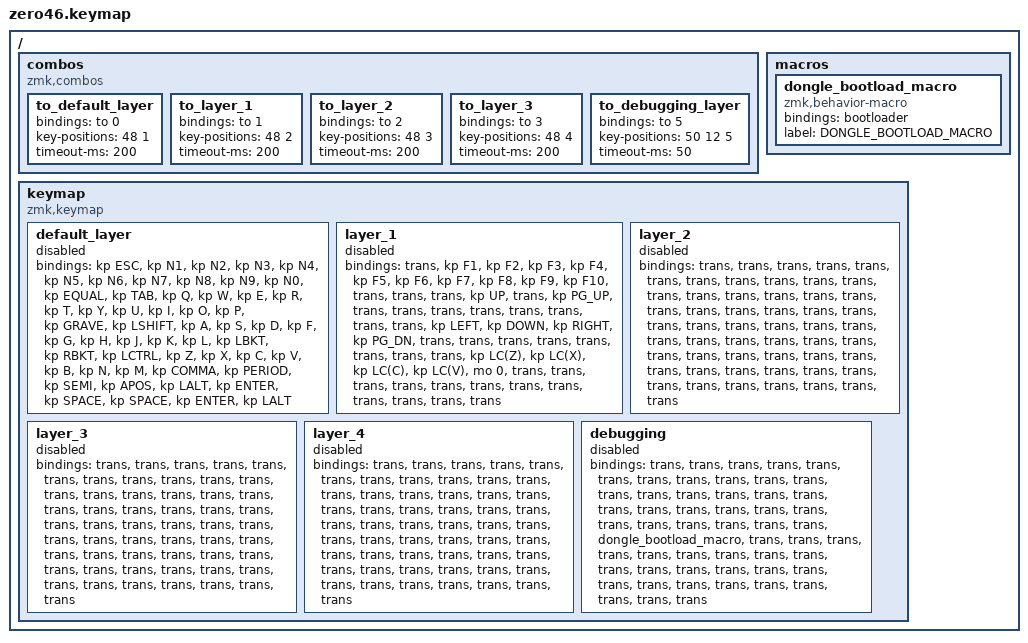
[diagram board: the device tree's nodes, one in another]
/*
 * Copyright (c) 2021 The ZMK Contributors
 *
 * SPDX-License-Identifier: MIT
 */
#define ZMK_BEHAVIORS_OMIT_KT
#include <behaviors.dtsi>
#include <dt-bindings/zmk/keys.h>

/ {
    combos {
        compatible = "zmk,combos";

        to_default_layer {
            bindings = <&to 0>;
            key-positions = <48 1>;
            timeout-ms = <200>;
        };

        to_layer_1 {
            bindings = <&to 1>;
            key-positions = <48 2>;
            timeout-ms = <200>;
        };

        to_layer_2 {
            bindings = <&to 2>;
            key-positions = <48 3>;
            timeout-ms = <200>;
        };

        to_layer_3 {
            bindings = <&to 3>;
            key-positions = <48 4>;
            timeout-ms = <200>;
        };

        to_debugging_layer {
            bindings = <&to 5>;
            key-positions = <50 12 5>;
            timeout-ms = <50>;
        };
    };

    macros {
        dongle_bootload_macro: dongle_bootload_macro {
            compatible = "zmk,behavior-macro";
            #binding-cells = <0>;
            bindings = <&bootloader>;
            label = "DONGLE_BOOTLOAD_MACRO";
        };
    };

    keymap {
        compatible = "zmk,keymap";

        default_layer {
            // ---------------------------------------------------------------------------------------------------------------
            // | ESC   |  1  |  2   |   3   |  4    |  5   |   ---   |   6   |   7   |   8   |   9   |   0   |  =|+  |
            // | TAB   |  Q  |  W   |   E   |  R    |  T   |   ---   |   Y   |   U   |   I   |   O   |   P   |  `|~  |
            // | SHIFT |  A  |  S   |   D   |  F    |  G   |   ---   |   H   |   J   |   K   |   L   |  [|{  |  ]|}  |
            // | CRTL  |  Z  |  X   |   C   |  V    |  B   |   ---   |   N   |   M   |  ,|<  |  .|>  |  ;|:  |  '|"  |
            //                      |  ALT  | ENTER | KSPC |   ---   | KSPC  | ENTER |  ALT  |
            status = "reserved";
            bindings = <
&kp ESC     &kp N1  &kp N2  &kp N3    &kp N4     &kp N5             &kp N6       &kp N7     &kp N8     &kp N9      &kp N0    &kp EQUAL
&kp TAB     &kp Q   &kp W   &kp E     &kp R      &kp T              &kp Y        &kp U      &kp I      &kp O       &kp P     &kp GRAVE
&kp LSHIFT  &kp A   &kp S   &kp D     &kp F      &kp G              &kp H        &kp J      &kp K      &kp L       &kp LBKT  &kp RBKT
&kp LCTRL   &kp Z   &kp X   &kp C     &kp V      &kp B              &kp N        &kp M      &kp COMMA  &kp PERIOD  &kp SEMI  &kp APOS
                            &kp LALT  &kp ENTER  &kp SPACE          &kp SPACE    &kp ENTER  &kp LALT
            >;
        };

        layer_1 {
            status = "reserved";
            bindings = <
&trans  &kp F1     &kp F2     &kp F3     &kp F4     &kp F5          &kp F6    &kp F7  &kp F8  &kp F9  &kp F10  &trans
&trans  &trans     &kp UP     &trans     &kp PG_UP  &trans          &trans    &trans  &trans  &trans  &trans   &trans
&trans  &kp LEFT   &kp DOWN   &kp RIGHT  &kp PG_DN  &trans          &trans    &trans  &trans  &trans  &trans   &trans
&trans  &kp LC(Z)  &kp LC(X)  &kp LC(C)  &kp LC(V)  &mo 0           &trans    &trans  &trans  &trans  &trans   &trans
                              &trans     &trans     &trans          &trans    &trans  &trans
            >;
        };


        layer_2 {
            status = "reserved";
            bindings = <
&trans  &trans  &trans  &trans  &trans  &trans          &trans    &trans  &trans  &trans  &trans  &trans
&trans  &trans  &trans  &trans  &trans  &trans          &trans    &trans  &trans  &trans  &trans  &trans
&trans  &trans  &trans  &trans  &trans  &trans          &trans    &trans  &trans  &trans  &trans  &trans
&trans  &trans  &trans  &trans  &trans  &trans          &trans    &trans  &trans  &trans  &trans  &trans
                        &trans  &trans  &trans          &trans    &trans  &trans
            >;
        };

        layer_3 {
            status = "reserved";
            bindings = <
&trans  &trans  &trans  &trans  &trans  &trans          &trans    &trans  &trans  &trans  &trans  &trans
&trans  &trans  &trans  &trans  &trans  &trans          &trans    &trans  &trans  &trans  &trans  &trans
&trans  &trans  &trans  &trans  &trans  &trans          &trans    &trans  &trans  &trans  &trans  &trans
&trans  &trans  &trans  &trans  &trans  &trans          &trans    &trans  &trans  &trans  &trans  &trans
                        &trans  &trans  &trans          &trans    &trans  &trans
            >;
        };

        layer_4 {
            status = "reserved";
            bindings = <
&trans  &trans  &trans  &trans  &trans  &trans          &trans    &trans  &trans  &trans  &trans  &trans
&trans  &trans  &trans  &trans  &trans  &trans          &trans    &trans  &trans  &trans  &trans  &trans
&trans  &trans  &trans  &trans  &trans  &trans          &trans    &trans  &trans  &trans  &trans  &trans
&trans  &trans  &trans  &trans  &trans  &trans          &trans    &trans  &trans  &trans  &trans  &trans
                        &trans  &trans  &trans          &trans    &trans  &trans
            >;
        };

        debugging {
            status = "reserved";
            bindings = <
&trans  &trans  &trans  &trans  &trans  &trans                          &trans    &trans  &trans  &trans  &trans  &trans
&trans  &trans  &trans  &trans  &trans  &trans                          &trans    &trans  &trans  &trans  &trans  &trans
&trans  &trans  &trans  &trans  &trans  &dongle_bootload_macro          &trans    &trans  &trans  &trans  &trans  &trans
&trans  &trans  &trans  &trans  &trans  &trans                          &trans    &trans  &trans  &trans  &trans  &trans
                        &trans  &trans  &trans                          &trans    &trans  &trans
            >;
        };
    };
};
